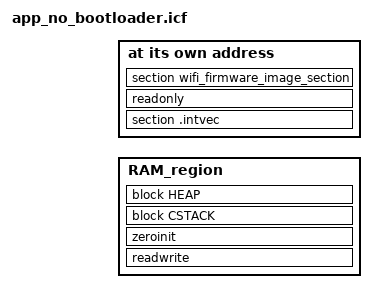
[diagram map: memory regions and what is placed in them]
/*
 * Broadcom Proprietary and Confidential. Copyright 2016 Broadcom
 * All Rights Reserved.
 *
 * This is UNPUBLISHED PROPRIETARY SOURCE CODE of Broadcom Corporation;
 * the contents of this file may not be disclosed to third parties, copied
 * or duplicated in any form, in whole or in part, without the prior
 * written permission of Broadcom Corporation.
 */

/* Define memory symbols */
include "memory_no_bootloader.icf";

/* Define memory regions */
define memory mem with size = 4G;
define region ROM_region   = mem:[from __App_start   to __App_end];
define region RAM_region   = mem:[from __SRAM_start   to __SRAM_end];


/* create a stack block */
define block CSTACK    with alignment = 8, size = __STACKSIZE__   { };
/* create a heap block */
define block HEAP      with alignment = 8, size = 0x10000     { };

/* place application and its data */
place at address mem:(__App_start ) { section .intvec, readonly, section wifi_firmware_image_section };

initialize by copy { readwrite };


place in RAM_region   { readwrite,
                        zeroinit,
                        block CSTACK,
                        block HEAP,
                      };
